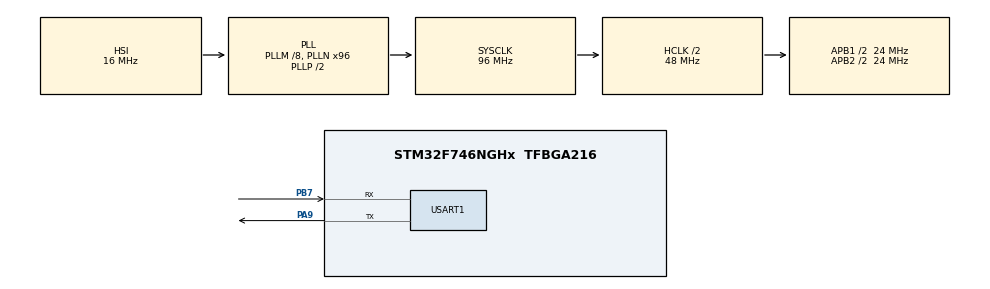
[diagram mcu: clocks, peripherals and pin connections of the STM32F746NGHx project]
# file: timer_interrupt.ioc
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Mcu.Family=STM32F7
RCC.PLLSourceVirtual=RCC_PLLSOURCE_HSI
RCC.CortexFreq_Value=48000000
NVIC.TIM6_DAC_IRQn=true\:0\:0\:false\:false\:true\:true\:true
TIM6.Prescaler=47999
VP_TIM6_VS_ClockSourceINT.Mode=Enable_Timer
RCC.APB1CLKDivider=RCC_HCLK_DIV2
RCC.SYSCLKSource=RCC_SYSCLKSOURCE_PLLCLK
ProjectManager.StackSize=0x400
USART1.VirtualMode-Asynchronous=VM_ASYNC
TIM6.AutoReloadPreload=TIM_AUTORELOAD_PRELOAD_ENABLE
PA9.Mode=Asynchronous
ProjectManager.TargetToolchain=STM32CubeIDE
RCC.HCLKFreq_Value=48000000
RCC.APB2TimFreq_Value=48000000
PA9.Signal=USART1_TX
RCC.USBFreq_Value=96000000
RCC.LSE_VALUE=32768
RCC.AHBFreq_Value=48000000
RCC.HSE_VALUE=25000000
board=STM32F746G-DISCO
RCC.VCOOutputFreq_Value=192000000
RCC.APB2Freq_Value=24000000
PB7.Signal=USART1_RX
RCC.AHBCLKDivider=RCC_SYSCLK_DIV2
TIM6.Period=4999
Mcu.Name=STM32F746NGHx
RCC.SYSCLKFreq_VALUE=96000000
Mcu.Package=TFBGA216
PB7.Mode=Asynchronous
ProjectManager.HeapSize=0x200
RCC.HSI_VALUE=16000000
NVIC.PriorityGroup=NVIC_PRIORITYGROUP_4
RCC.APB2CLKDivider=RCC_HCLK_DIV2
RCC.PLLM=8
RCC.PLLN=96
RCC.APB1TimFreq_Value=48000000
RCC.APB1Freq_Value=24000000

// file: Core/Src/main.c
/* USER CODE BEGIN Header */
/**
  ******************************************************************************
  * @file           : main.c
  * @brief          : Main program body
  ******************************************************************************
  * @attention
  *
  * <h2><center>&copy; Copyright (c) 2021 STMicroelectronics.
  * All rights reserved.</center></h2>
  *
  * This software component is licensed by ST under BSD 3-Clause license,
  * the "License"; You may not use this file except in compliance with the
  * License. You may obtain a copy of the License at:
  *                        opensource.org/licenses/BSD-3-Clause
  *
  ******************************************************************************
  */
/* USER CODE END Header */
#include "main.h"

TIM_HandleTypeDef htim6;

UART_HandleTypeDef huart1;

void SystemClock_Config(void);
static void MX_GPIO_Init(void);
static void MX_TIM6_Init(void);
static void MX_USART1_UART_Init(void);

/* USER CODE BEGIN 0 */
void HAL_TIM_PeriodElapsedCallback(TIM_HandleTypeDef *htim)
{
	if (htim->Instance == TIM6)
	{
		HAL_UART_Transmit(&huart1, (uint8_t*)"Timer Elapsed\r\n", 15, HAL_MAX_DELAY);
	}
}
/* USER CODE END 0 */

int main(void)
{

  /* MCU Configuration--------------------------------------------------------*/

  /* Reset of all peripherals, Initializes the Flash interface and the Systick. */
  HAL_Init();

  /* Configure the system clock */
  SystemClock_Config();

  /* Initialize all configured peripherals */
  MX_GPIO_Init();
  MX_TIM6_Init();
  MX_USART1_UART_Init();
  /* USER CODE BEGIN 2 */
  HAL_TIM_Base_Start_IT(&htim6);
  /* USER CODE END 2 */

  /* Infinite loop */
  while (1)
  {

  }
}

void SystemClock_Config(void)
{
  RCC_OscInitTypeDef RCC_OscInitStruct = {0};
  RCC_ClkInitTypeDef RCC_ClkInitStruct = {0};
  RCC_PeriphCLKInitTypeDef PeriphClkInitStruct = {0};

  /** Configure the main internal regulator output voltage
  */
  __HAL_RCC_PWR_CLK_ENABLE();
  __HAL_PWR_VOLTAGESCALING_CONFIG(PWR_REGULATOR_VOLTAGE_SCALE3);
  /** Initializes the RCC Oscillators according to the specified parameters
  * in the RCC_OscInitTypeDef structure.
  */
  RCC_OscInitStruct.OscillatorType = RCC_OSCILLATORTYPE_HSI;
  RCC_OscInitStruct.HSIState = RCC_HSI_ON;
  RCC_OscInitStruct.HSICalibrationValue = RCC_HSICALIBRATION_DEFAULT;
  RCC_OscInitStruct.PLL.PLLState = RCC_PLL_ON;
  RCC_OscInitStruct.PLL.PLLSource = RCC_PLLSOURCE_HSI;
  RCC_OscInitStruct.PLL.PLLM = 8;
  RCC_OscInitStruct.PLL.PLLN = 96;
  RCC_OscInitStruct.PLL.PLLP = RCC_PLLP_DIV2;
  RCC_OscInitStruct.PLL.PLLQ = 2;
  if (HAL_RCC_OscConfig(&RCC_OscInitStruct) != HAL_OK)
  {
    Error_Handler();
  }
  /** Initializes the CPU, AHB and APB buses clocks
  */
  RCC_ClkInitStruct.ClockType = RCC_CLOCKTYPE_HCLK|RCC_CLOCKTYPE_SYSCLK
                              |RCC_CLOCKTYPE_PCLK1|RCC_CLOCKTYPE_PCLK2;
  RCC_ClkInitStruct.SYSCLKSource = RCC_SYSCLKSOURCE_PLLCLK;
  RCC_ClkInitStruct.AHBCLKDivider = RCC_SYSCLK_DIV2;
  RCC_ClkInitStruct.APB1CLKDivider = RCC_HCLK_DIV2;
  RCC_ClkInitStruct.APB2CLKDivider = RCC_HCLK_DIV2;

  if (HAL_RCC_ClockConfig(&RCC_ClkInitStruct, FLASH_LATENCY_1) != HAL_OK)
  {
    Error_Handler();
  }
  PeriphClkInitStruct.PeriphClockSelection = RCC_PERIPHCLK_USART1;
  PeriphClkInitStruct.Usart1ClockSelection = RCC_USART1CLKSOURCE_PCLK2;
  if (HAL_RCCEx_PeriphCLKConfig(&PeriphClkInitStruct) != HAL_OK)
  {
    Error_Handler();
  }
}

static void MX_TIM6_Init(void)
{

  TIM_MasterConfigTypeDef sMasterConfig = {0};

  htim6.Instance = TIM6;
  htim6.Init.Prescaler = 47999;
  htim6.Init.CounterMode = TIM_COUNTERMODE_UP;
  htim6.Init.Period = 4999;
  htim6.Init.AutoReloadPreload = TIM_AUTORELOAD_PRELOAD_ENABLE;
  if (HAL_TIM_Base_Init(&htim6) != HAL_OK)
  {
    Error_Handler();
  }
  sMasterConfig.MasterOutputTrigger = TIM_TRGO_RESET;
  sMasterConfig.MasterSlaveMode = TIM_MASTERSLAVEMODE_DISABLE;
  if (HAL_TIMEx_MasterConfigSynchronization(&htim6, &sMasterConfig) != HAL_OK)
  {
    Error_Handler();
  }

}

static void MX_USART1_UART_Init(void)
{

  huart1.Instance = USART1;
  huart1.Init.BaudRate = 115200;
  huart1.Init.WordLength = UART_WORDLENGTH_8B;
  huart1.Init.StopBits = UART_STOPBITS_1;
  huart1.Init.Parity = UART_PARITY_NONE;
  huart1.Init.Mode = UART_MODE_TX_RX;
  huart1.Init.HwFlowCtl = UART_HWCONTROL_NONE;
  huart1.Init.OverSampling = UART_OVERSAMPLING_16;
  huart1.Init.OneBitSampling = UART_ONE_BIT_SAMPLE_DISABLE;
  huart1.AdvancedInit.AdvFeatureInit = UART_ADVFEATURE_NO_INIT;
  if (HAL_UART_Init(&huart1) != HAL_OK)
  {
    Error_Handler();
  }

}

static void MX_GPIO_Init(void)
{

  /* GPIO Ports Clock Enable */
  __HAL_RCC_GPIOB_CLK_ENABLE();
  __HAL_RCC_GPIOA_CLK_ENABLE();

}

void Error_Handler(void)
{
}

/************************ (C) COPYRIGHT STMicroelectronics *****END OF FILE****/
